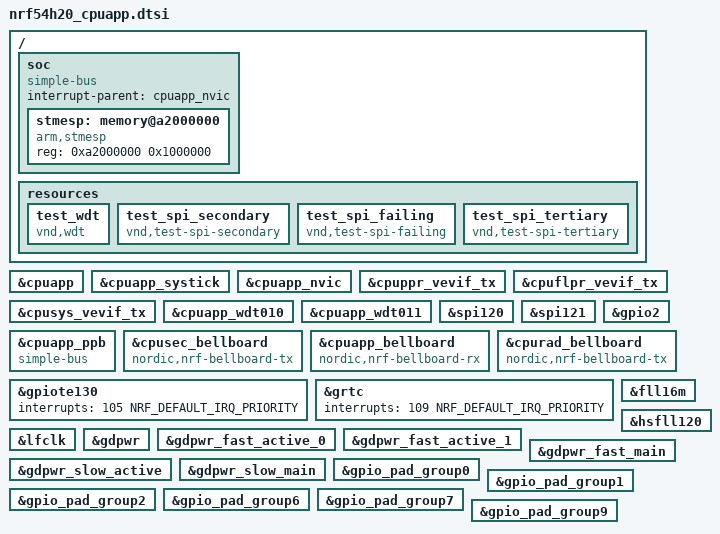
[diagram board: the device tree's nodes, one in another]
/*
 * Copyright (c) 2024 Nordic Semiconductor ASA
 *
 * SPDX-License-Identifier: Apache-2.0
 */

#include <nordic/nrf54h20.dtsi>

cpu: &cpuapp {};
systick: &cpuapp_systick {};
nvic: &cpuapp_nvic {};
cpuppr_vevif: &cpuppr_vevif_tx {};
cpuflpr_vevif: &cpuflpr_vevif_tx {};
cpusys_vevif: &cpusys_vevif_tx {};
wdt010: &cpuapp_wdt010 {};
wdt011: &cpuapp_wdt011 {};

/delete-node/ &cpuppr;
/delete-node/ &cpuflpr;
/delete-node/ &cpurad;
/delete-node/ &cpurad_peripherals;
/delete-node/ &cpurad_ppb;
/delete-node/ &cpurad_ram0;

/ {
	soc {
		compatible = "simple-bus";
		interrupt-parent = <&cpuapp_nvic>;
		ranges;

		stmesp: memory@a2000000 {
			compatible = "arm,stmesp";
			reg = <0xa2000000 0x1000000>;
		};
	};

	resources {
		test_wdt: test_wdt {
			compatible = "vnd,wdt";
			status = "okay";
		};

		test_spi_secondary: test_spi_secondary {
			compatible = "vnd,test-spi-secondary";
			status = "okay";
		};

		test_spi_failing: test_spi_failing {
			compatible = "vnd,test-spi-failing";
			status = "okay";
		};

		test_spi_tertiary: test_spi_tertiary {
			compatible = "vnd,test-spi-tertiary";
			status = "okay";
		};
	};
};

/* vnd,wdt */
#define WDT_ENABLE
wdt_enable: &wdt010{};

/* vnd,test-spi */
#define SPI_ENABLE
spi_enable: &spi120{};
#define SPI_PORT 7
#define SPI_MISO 6
#define SPI_SCK  3
#define SPI_MOSI 7
#define SPI_FREQ_SLOW DT_FREQ_M(4)
#define SPI_FREQ_FAST DT_FREQ_M(8)
#define SPI_DRIVE_MODE NRF_DRIVE_E0E1
#define SPI_MEM_REG

/* vnd,test-spi-secondary */
#define SPI_SECONDARY_MEM_REG

/* vnd,test-spi-failing */
#define SPI_FREQ_FAILING DT_FREQ_M(2)

/* vnd,test-spi-tertiary */
#define SPI_TERTIARY_ENABLE
spi_tertiary_enable: &spi121{};
#define SPI_TERTIARY_PORT 2
#define SPI_TERTIARY_MISO 10
#define SPI_TERTIARY_SCK  2
#define SPI_TERTIARY_MOSI 11
#define SPI_TERTIARY_FREQ_SLOW DT_FREQ_M(4)
#define SPI_TERTIARY_FREQ_FAST DT_FREQ_M(8)
#define SPI_TERTIARY_DRIVE_MODE NRF_DRIVE_E0E1
#define SPI_TERTIARY_MEM_REG
#define SPI_TERTIARY_NFC_DISABLE
#define SPI_TERTIARY_GPIO_ENABLE
spi_tertiary_gpio_enable: &gpio2{};

//TODO: move CONFIG_SPI_IDEAL_TRANSFER_DURATION_SCALING to DT

&cpuapp_ppb {
	compatible = "simple-bus";
	ranges;
};

&cpusec_bellboard {
	compatible = "nordic,nrf-bellboard-tx";
};

&cpuapp_bellboard {
	compatible = "nordic,nrf-bellboard-rx";
};

&cpurad_bellboard {
	compatible = "nordic,nrf-bellboard-tx";
};

&gpiote130 {
	interrupts = <105 NRF_DEFAULT_IRQ_PRIORITY>;
};

&grtc {
	interrupts = <109 NRF_DEFAULT_IRQ_PRIORITY>;
};

&fll16m  {
	status = "okay";
};

&hsfll120  {
	status = "okay";
};

&lfclk  {
	status = "okay";
};

&gdpwr {
	status = "okay";
};

&gdpwr_fast_active_0 {
	status = "okay";
};

&gdpwr_fast_active_1 {
	status = "okay";
};

&gdpwr_fast_main {
	status = "okay";
};

&gdpwr_slow_active {
	status = "okay";
};

&gdpwr_slow_main {
	status = "okay";
};

&gpio_pad_group0 {
	status = "okay";
};

&gpio_pad_group1 {
	status = "okay";
};

&gpio_pad_group2 {
	status = "okay";
};

&gpio_pad_group6 {
	status = "okay";
};

&gpio_pad_group7 {
	status = "okay";
};

&gpio_pad_group9 {
	status = "okay";
};
